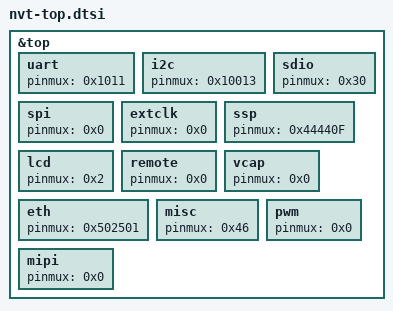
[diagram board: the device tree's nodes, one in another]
&top {
	uart{pinmux = <0x1011>;};
	i2c{pinmux = <0x10013>;};
	sdio{pinmux = <0x30>;};
	spi{pinmux = <0x0>;};
	extclk{pinmux = <0x0>;};
	ssp{pinmux = <0x44440F>;};
	lcd{pinmux = <0x2>;};/*0x2=lcd0-same-lcd1(x/x/ext_hdmi) 0x200=lcd0(xxx)-diff-lcd1(ext_hdmi) */
	remote{pinmux = <0x0>;};
	vcap{pinmux = <0x0>;};
	eth{pinmux = <0x502501>;};
	misc{pinmux = <0x46>;};
	pwm{pinmux = <0x0>;};
	mipi{pinmux = <0x0>;};
};
